AUTOSAR XML (schema 4-3-0)
standard types defined: boolean_DataConstr, sint8_DataConstr, sint16_DataConstr, sint32_DataConstr, uint8_DataConstr, uint16_DataConstr, uint32_DataConstr, uint64_DataConstr, boolean, float32, sint8, sint16, sint32, uint8, uint16, uint32, uint64
package /Package_TestSWC2/DataTypes/ImplementationTypes
  impl type st_color1: category=STRUCTURE
    element red: implementation-data-type=float32
    element blue: implementation-data-type=boolean
  impl type st_color2: category=STRUCTURE
    element white: implementation-data-type=boolean
    element black: implementation-data-type=uint8
  impl type uint8_array_32_CS: category=ARRAY
    element uint8_array_32_CS: array-size=32, array-size-semantics=FIXED-SIZE, implementation-data-type=uint8
package /Package_TestSWC2/PortInterfaces
  sender receiver interface in1  # in1_xxxx
    data in1: type=boolean
  sender receiver interface out1  # out1_xxxx
    data out1: type=boolean
  sender receiver interface out2  # out2_xxxx
    data out2: type=uint8
  client server interface PiNVMP_GetAswBlockErrSts
    operation GetAswBlockErrSts: possible-error=E_NOT_OK
      arg AswBlockId: type=uint32, direction=IN, server-argument-impl-policy=USE-ARGUMENT-TYPE
      arg AswBlockErrSts: type=uint8_array_32_CS, direction=OUT, server-argument-impl-policy=USE-ARGUMENT-TYPE
    error E_NOT_OK: error-code=1
package /Package_TestSWC2/ComponentTypes
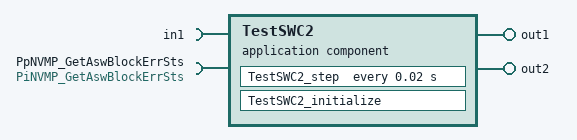
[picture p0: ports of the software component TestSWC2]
  application sw component type TestSWC2
    provide port out1: nonqueued-sender-com-spec{data-element=out1, init-value=0}, provided-interface=out1
    provide port out2: nonqueued-sender-com-spec{data-element=out2, init-value=0}, provided-interface=out2
    require port in1: nonqueued-receiver-com-spec{data-element=in1, filter=data-filter-type=ALWAYS, init-value=1}, required-interface=in1
    require port PpNVMP_GetAswBlockErrSts: client-com-spec=GetAswBlockErrSts, required-interface=PiNVMP_GetAswBlockErrSts
    behavior TestSWC2_InternalBehavior
      timing event Event_Runnable_Step: start-on-event=TestSWC2_step, period=0.02
      init event Event_Runnable_Init: start-on-event=TestSWC2_initialize
      port-api-options:
        enable-take-address=false, indirect-api=false, port=in1
        enable-take-address=false, indirect-api=false, port=out1
        enable-take-address=false, indirect-api=false, port=out2
        enable-take-address=false, indirect-api=false, port=PpNVMP_GetAswBlockErrSts
      runnable TestSWC2_step
        data-receive-point-by-arguments:
          access REC_in1_in1: accessed-variable=in1.in1
        data-send-points:
          access SEND_out1_out1: accessed-variable=out1.out1
          access SEND_out2_out2: accessed-variable=out2.out2
        sync call SC_PpNVMP_GetAswBlockErrSts_GetAswBlockErrSts: operation=PpNVMP_GetAswBlockErrSts.GetAswBlockErrSts, timeout=0
      runnable TestSWC2_initialize
  swc implementation TestSWC2_Implementation: behavior=TestSWC2_InternalBehavior
